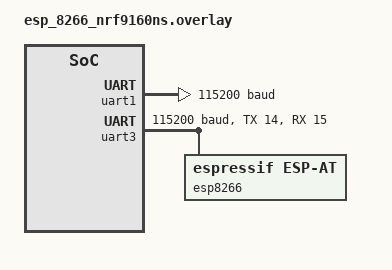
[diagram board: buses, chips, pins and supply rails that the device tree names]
/* Copyright (c) 2021 Nordic Semiconductor ASA
 *
 * SPDX-License-Identifier: LicenseRef-Nordic-5-Clause
 */

 /*
  * DTS overlay to be used with connecting nRF9160DK with ESP8266-01 using
  * esp_at driver.
  *
  * https://en.wikipedia.org/wiki/ESP8266
  *
  * Wiring:
  * - Slide (SW9) to enable 3V mode.
  * - ESP8266 RX → DK P0.14 (TX)
  * - ESP8266 TX → DK P0.15 (RX)
  * - ESP8266 VCC → DK VDD
  * - ESP8266 CH_PD → DK VDD
  * - ESP8266 GND → DK GND.
  *
  * Compilation with SW overlay:
  * 'west build -p -b nrf9160dk_nrf9160_ns -- -DDTC_OVERLAY_FILE=esp_8266_nrf9160ns.overlay -DOVERLAY_CONFIG=overlay-esp-wifi.conf'
  */

&uart1 {
	status = "okay";
	current-speed = <115200>;
	rts-pin = <0xffffffff>;
	cts-pin = <0xffffffff>;
};

&uart3 {
	status = "okay";
	current-speed = <115200>;
	tx-pin = < 0xe >;
	rx-pin = < 0xf >;
	rts-pin = <0xffffffff>;
	cts-pin = <0xffffffff>;

	esp8266 {
		compatible = "espressif,esp-at";
		label = "esp8266";
		status = "okay";
	};
};
